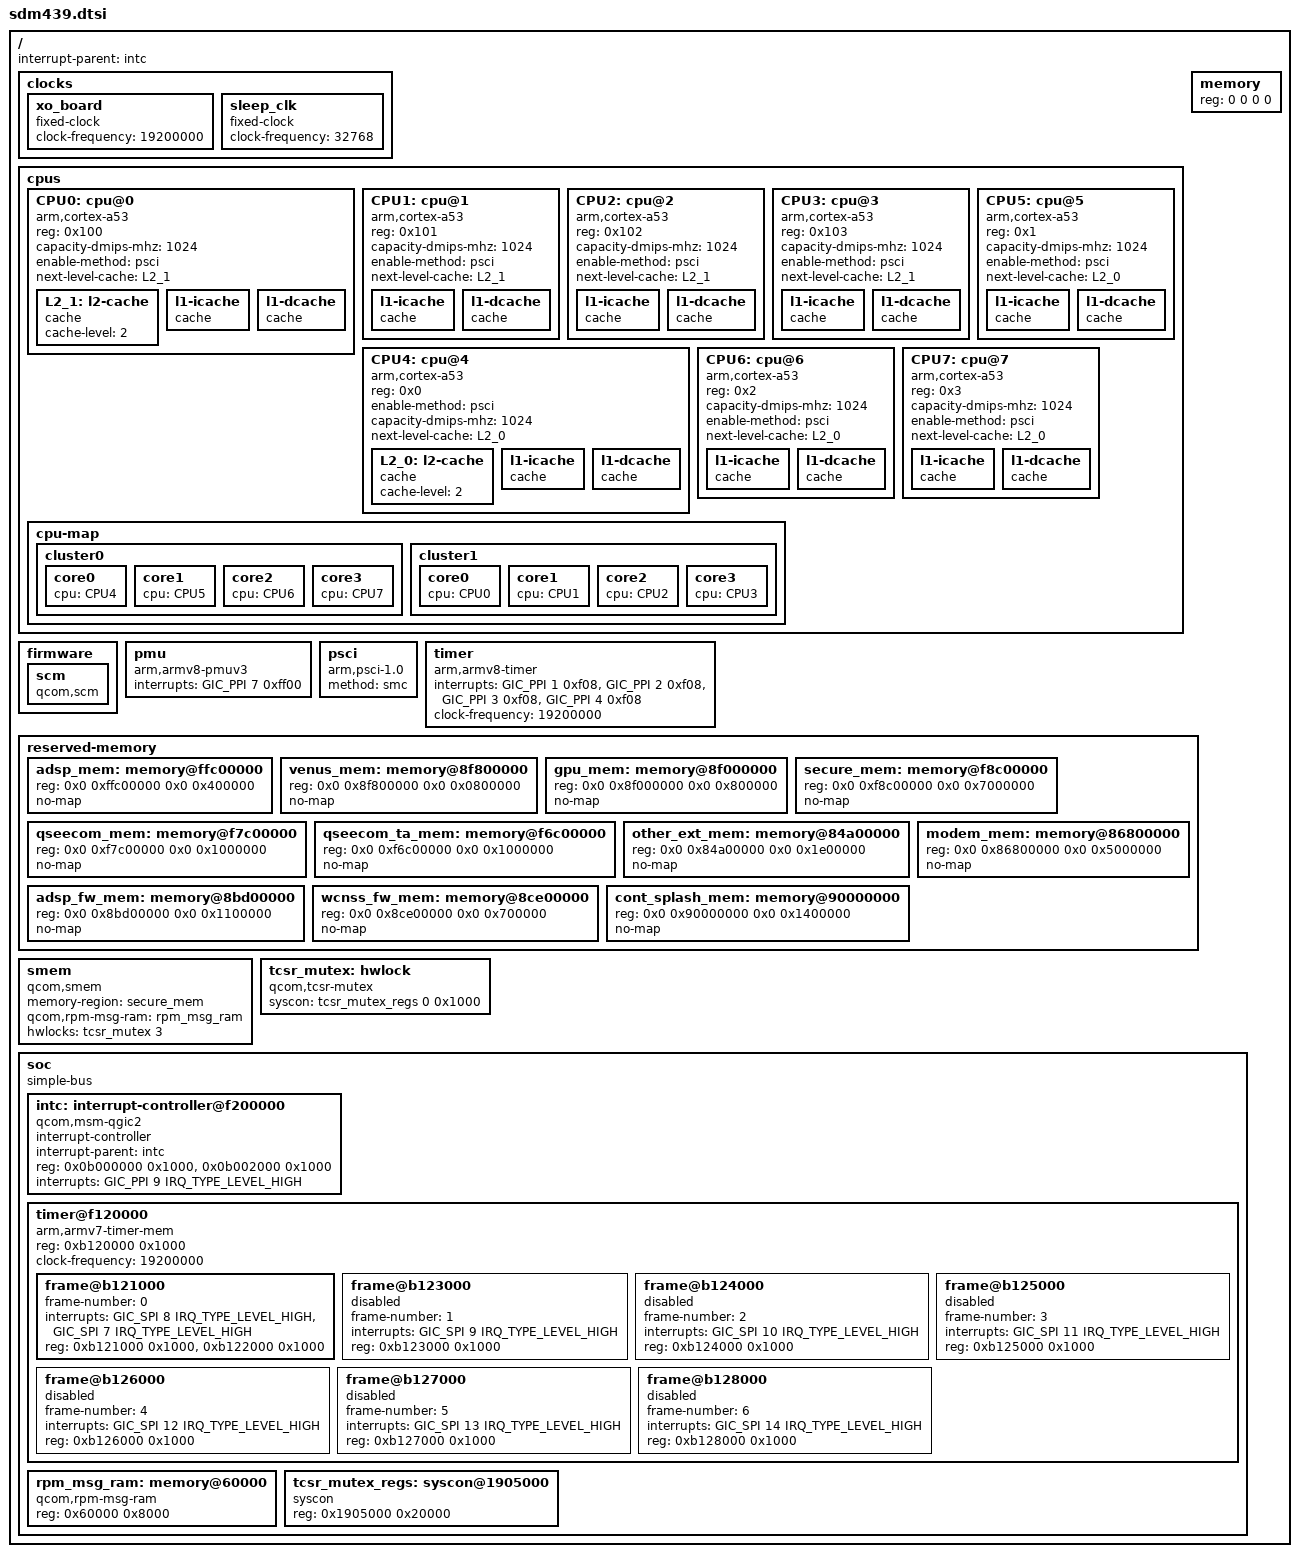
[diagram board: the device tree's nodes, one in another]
// SPDX-License-Identifier: GPL-2.0-only

#include <dt-bindings/interrupt-controller/arm-gic.h>

/ {
	interrupt-parent = <&intc>;

	#address-cells = <2>;
	#size-cells = <2>;

	clocks {
		xo_board: xo_board {
			compatible = "fixed-clock";
			clock-frequency = <19200000>;
			#clock-cells = <1>;
		};

		sleep_clk: sleep_clk {
			compatible = "fixed-clock";
			clock-frequency = <32768>;
			#clock-cells = <1>;
		};
	};

	cpus {
		#address-cells = <1>;
		#size-cells = <0>;

		CPU0: cpu@0 {
			device_type = "cpu";
			compatible = "arm,cortex-a53";
			reg = <0x100>;
			capacity-dmips-mhz = <1024>;
			enable-method = "psci";
			next-level-cache = <&L2_1>;
			L2_1: l2-cache {
				compatible = "cache";
				cache-level = <2>;
			};

			l1-icache { compatible = "cache"; };
			l1-dcache { compatible = "cache"; };
		};

		CPU1: cpu@1 {
			device_type = "cpu";
			compatible = "arm,cortex-a53";
			reg = <0x101>;
			capacity-dmips-mhz = <1024>;
			enable-method = "psci";
			next-level-cache = <&L2_1>;
			l1-icache { compatible = "cache"; };
			l1-dcache { compatible = "cache"; };
		};

		CPU2: cpu@2 {
			device_type = "cpu";
			compatible = "arm,cortex-a53";
			reg = <0x102>;
			capacity-dmips-mhz = <1024>;
			enable-method = "psci";
			next-level-cache = <&L2_1>;
			l1-icache { compatible = "cache"; };
			l1-dcache { compatible = "cache"; };
		};

		CPU3: cpu@3 {
			device_type = "cpu";
			compatible = "arm,cortex-a53";
			reg = <0x103>;
			capacity-dmips-mhz = <1024>;
			enable-method = "psci";
			next-level-cache = <&L2_1>;
			l1-icache { compatible = "cache"; };
			l1-dcache { compatible = "cache"; };
		};

		CPU4: cpu@4 {
			device_type = "cpu";
			compatible = "arm,cortex-a53";
			reg = <0x0>;
			enable-method = "psci";
			capacity-dmips-mhz = <1024>;
			next-level-cache = <&L2_0>;
			L2_0: l2-cache {
				compatible = "cache";
				cache-level = <2>;
			};

			l1-icache { compatible = "cache"; };
			l1-dcache { compatible = "cache"; };
		};

		CPU5: cpu@5 {
			device_type = "cpu";
			compatible = "arm,cortex-a53";
			reg = <0x1>;
			capacity-dmips-mhz = <1024>;
			enable-method = "psci";
			next-level-cache = <&L2_0>;
			l1-icache { compatible = "cache"; };
			l1-dcache { compatible = "cache"; };
		};

		CPU6: cpu@6 {
			device_type = "cpu";
			compatible = "arm,cortex-a53";
			reg = <0x2>;
			capacity-dmips-mhz = <1024>;
			enable-method = "psci";
			next-level-cache = <&L2_0>;
			l1-icache { compatible = "cache"; };
			l1-dcache { compatible = "cache"; };
		};

		CPU7: cpu@7 {
			device_type = "cpu";
			compatible = "arm,cortex-a53";
			reg = <0x3>;
			capacity-dmips-mhz = <1024>;
			enable-method = "psci";
			next-level-cache = <&L2_0>;
			l1-icache { compatible = "cache"; };
			l1-dcache { compatible = "cache"; };
		};

		cpu-map {
			cluster0 {
				core0 {
					cpu = <&CPU4>;
				};

				core1 {
					cpu = <&CPU5>;
				};

				core2 {
					cpu = <&CPU6>;
				};

				core3 {
					cpu = <&CPU7>;
				};
			};

			cluster1 {
				core0 {
					cpu = <&CPU0>;
				};

				core1 {
					cpu = <&CPU1>;
				};

				core2 {
					cpu = <&CPU2>;
				};

				core3 {
					cpu = <&CPU3>;
				};
			};
		};
	};

	firmware {
		scm {
			compatible = "qcom,scm";
		};
	};

	memory {
		device_type = "memory";
		/* We expect the bootloader to fill in the reg */
		reg = <0 0 0 0>;
	};

	pmu {
		compatible = "arm,armv8-pmuv3";
		interrupts = <GIC_PPI 7 0xff00>;
	};

	psci {
		compatible = "arm,psci-1.0";
		method = "smc";
	};

	timer {
		compatible = "arm,armv8-timer";
		interrupts = <GIC_PPI 1 0xf08>,
			     <GIC_PPI 2 0xf08>,
			     <GIC_PPI 3 0xf08>,
			     <GIC_PPI 4 0xf08>;
		clock-frequency = <19200000>;
	};

	reserved-memory {
		#address-cells = <2>;
		#size-cells = <2>;
		ranges;

		adsp_mem: memory@ffc00000 {
			reg = <0x0 0xffc00000 0x0 0x400000>;
			no-map;
		};

		/* dump_mem: memory@8f800000 {
			reg = <0x0 0x8f800000 0x0 0x400000>;
			no-map;
		}; */

		venus_mem: memory@8f800000 {
			reg = <0x0 0x8f800000 0x0 0x0800000>;
			no-map;
		};

		gpu_mem: memory@8f000000 {
			reg = <0x0 0x8f000000 0x0 0x800000>;
			no-map;
		};

		secure_mem: memory@f8c00000 {
			reg = <0x0 0xf8c00000 0x0 0x7000000>;
			no-map;
		};

		qseecom_mem: memory@f7c00000 {
			reg = <0x0 0xf7c00000 0x0 0x1000000>;
			no-map;
		};

		qseecom_ta_mem: memory@f6c00000 {
			reg = <0x0 0xf6c00000 0x0 0x1000000>;
			no-map;
		};

		other_ext_mem: memory@84a00000 {
			reg = <0x0 0x84a00000 0x0 0x1e00000>;
			no-map;
		};

		modem_mem: memory@86800000 {
			reg = <0x0 0x86800000 0x0 0x5000000>;
			no-map;
		};

		adsp_fw_mem: memory@8bd00000 {
			reg = <0x0 0x8bd00000 0x0 0x1100000>;
			no-map;
		};

		wcnss_fw_mem: memory@8ce00000 {
			reg = <0x0 0x8ce00000 0x0 0x700000>;
			no-map;
		};

		cont_splash_mem: memory@90000000 {
			reg = <0x0 0x90000000 0x0 0x1400000>;
			no-map;
		};
	};

	smem {
		compatible = "qcom,smem";
		memory-region = <&secure_mem>;
		qcom,rpm-msg-ram = <&rpm_msg_ram>;
		hwlocks = <&tcsr_mutex 3>;
	};

	tcsr_mutex: hwlock {
		compatible = "qcom,tcsr-mutex";
		syscon = <&tcsr_mutex_regs 0 0x1000>;
		#hwlock-cells = <1>;
	};

	soc: soc {
		compatible = "simple-bus";
		#address-cells = <1>;
		#size-cells = <1>;
		ranges = <0 0 0 0xffffffff>;

		intc: interrupt-controller@f200000 {
			compatible = "qcom,msm-qgic2";
			#interrupt-cells = <3>;
			interrupt-controller;
			interrupt-parent = <&intc>;
			//#redistributor-regions = <1>;
			//redistributor-stride = <0x0 0x20000>;
			reg = <0x0b000000 0x1000>,     /* GICD */
			      <0x0b002000 0x1000>;    /* GICR * 8 */
			interrupts = <GIC_PPI 9 IRQ_TYPE_LEVEL_HIGH>;
		};

		timer@f120000 {
			compatible = "arm,armv7-timer-mem";
			#address-cells = <1>;
			#size-cells = <1>;
			ranges;
			reg = <0xb120000 0x1000>;
			clock-frequency = <19200000>;

			frame@b121000 {
				frame-number = <0>;
				interrupts = <GIC_SPI 8 IRQ_TYPE_LEVEL_HIGH>,
					     <GIC_SPI 7 IRQ_TYPE_LEVEL_HIGH>;
				reg = <0xb121000 0x1000>,
				      <0xb122000 0x1000>;
			};

			frame@b123000 {
				frame-number = <1>;
				interrupts = <GIC_SPI 9 IRQ_TYPE_LEVEL_HIGH>;
				reg = <0xb123000 0x1000>;
				status = "disabled";
			};

			frame@b124000 {
				frame-number = <2>;
				interrupts = <GIC_SPI 10 IRQ_TYPE_LEVEL_HIGH>;
				reg = <0xb124000 0x1000>;
				status = "disabled";
			};

			frame@b125000 {
				frame-number = <3>;
				interrupts = <GIC_SPI 11 IRQ_TYPE_LEVEL_HIGH>;
				reg = <0xb125000 0x1000>;
				status = "disabled";
			};

			frame@b126000 {
				frame-number = <4>;
				interrupts = <GIC_SPI 12 IRQ_TYPE_LEVEL_HIGH>;
				reg = <0xb126000 0x1000>;
				status = "disabled";
			};

			frame@b127000 {
				frame-number = <5>;
				interrupts = <GIC_SPI 13 IRQ_TYPE_LEVEL_HIGH>;
				reg = <0xb127000 0x1000>;
				status = "disabled";
			};

			frame@b128000 {
				frame-number = <6>;
				interrupts = <GIC_SPI 14 IRQ_TYPE_LEVEL_HIGH>;
				reg = <0xb128000 0x1000>;
				status = "disabled";
			};
		};

		rpm_msg_ram: memory@60000 {
			compatible = "qcom,rpm-msg-ram";
			reg = <0x60000 0x8000>;
		};

		tcsr_mutex_regs: syscon@1905000 {
			compatible = "syscon";
			reg = <0x1905000 0x20000>;
		};
	};
};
